# QEMU_VIRT register map
File version: 1.0
The devices of QEMU's virt machine for RISC-V that the interrupt e2e program uses.
Registers are 32-bit, read-write, no defined reset value unless marked. A register's access mark holds for its fields unless they carry their own. Offsets are from the block's base; lines under a group give offsets from that group; [hi:lo] are bit positions; {n}, {i} and the like mark numbered series; 'fields as' and 'values as' point back to an identical list; <NAME> marks a mode.

## Memory map
0x00100000 TEST — The test finisher: writing to it stops QEMU.
0x0C000000 PLIC — The platform-level interrupt controller.
0x10000000 UART0 — The 16550 UART: the console of the machine.

## Interrupts
10 UART0 — The UART, source 10 of the PLIC.

## UART0 — The 16550 UART: the console of the machine.
Base 0x10000000
0x00 RBR 8-bit ro — Receiver buffer: the byte received.
0x00 THR 8-bit wo — Transmitter holding register: the byte to send.
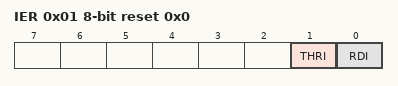
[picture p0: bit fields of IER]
0x01 IER 8-bit reset 0x0 — Interrupt enable: one bit per cause of interrupt, all off at reset.
  [1] THRI — An empty THR raises the interrupt.
  [0] RDI — A byte received raises the interrupt.
0x02 IIR 8-bit ro read-modifies — Interrupt identification: the cause of the interrupt. Reading it takes the THR empty cause.
  [3:0] CAUSE — 1 when no interrupt is raised, 2 for an empty THR, 4 for a byte received.

## TEST — The test finisher: writing to it stops QEMU.
Base 0x00100000
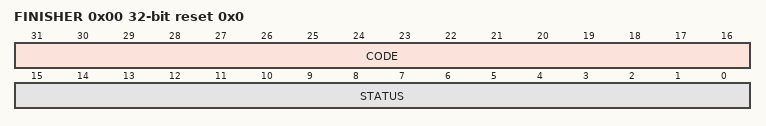
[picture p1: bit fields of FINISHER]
0x00 FINISHER wo reset 0x0 (reset mask 0xFFFF0000) — What to stop with.
  [31:16] CODE — The exit code of a failure.
  [15:0] STATUS — How the machine stops.
    0x3333=FAIL (Stops with failure, the exit code being CODE.); 0x5555=PASS (Stops with success.)

## PLIC — The platform-level interrupt controller.
Base 0x0C000000
{0x0+4i} PRIORITY[{i}] (i=0..95) — The priority of each source; QEMU keeps 3 bits. A source with priority 0 never interrupts.
{0x2000+0x80*i} ENABLE[{i}] (i=0..1) group — The sources a context takes: machine mode, then supervisor mode.
  {0x0+4j} SOURCES[{j}] (j=0..2) — Enable bits, 32 sources a word.
{0x200000+0x1000*i} CTX[{i}] (i=0..1) group — One context of hart 0: machine mode, then supervisor mode.
  0x00 THRESHOLD — The lowest priority the context takes.
  0x04 CLAIM read-modifies — Reading it takes the interrupt it names; writing the number back completes it.
